# HT32F52342_52 register map
File version: 1.0
The register description for the Holtek HT32F52342/52352
CPU: CM0+ r0p1, little endian, no MPU, no FPU, 4 interrupt priority bits
Registers are 32-bit, read-write, reset 0x0 unless marked. A register's access mark holds for its fields unless they carry their own. Offsets are from the block's base; lines under a group give offsets from that group; [hi:lo] are bit positions; {n}, {i} and the like mark numbered series; 'fields as' and 'values as' point back to an identical list; <NAME> marks a mode.

## Memory map
0x40000000 USART0 size 0x1000
0x40001000 UART0 size 0x1000
0x40004000 SPI0 size 0x1000
0x40010000 ADC size 0x1000
0x40022000 AFIO size 0x1000
0x40024000 EXTI size 0x1000
0x40026000 I2S size 0x1000
0x4002C000 MCTM0 size 0x1000
0x40034000 SCTM0 size 0x1000
0x40040000 USART1 size 0x1000
0x40041000 UART1 size 0x1000
0x40043000 SCI size 0x1000
0x40044000 SPI1 size 0x1000
0x40048000 I2C0 size 0x1000
0x40049000 I2C1 size 0x1000
0x40058000 CMP size 0x1000
0x40068000 WDT size 0x1000
0x4006A000 RTC size 0x1000
0x4006A100 PWRCU size 0x1000
0x4006E000 GPTM0 size 0x1000
0x4006F000 GPTM1 size 0x1000
0x40074000 SCTM1 size 0x1000
0x40076000 BFTM0 size 0x1000
0x40077000 BFTM1 size 0x1000
0x40080000 FMC size 0x1000
0x40088000 CKCU size 0x1000
0x40088100 RSTCU size 0x1000
0x4008A000 CRC size 0x1000
0x40090000 PDMA size 0x1000
0x40098000 EBI size 0x1000
0x400A8000 USB size 0x1000
0x400B0000 GPIOA size 0x1000
0x400B2000 GPIOB size 0x1000
0x400B4000 GPIOC size 0x1000
0x400B6000 GPIOD size 0x1000
0xE000E000 NVIC size 0x1000
0xE000E010 SysTick size 0x1000
0xE000ED00 SCB size 0x1000
0xE000ED30 Fault_Reports size 0x1000

## Interrupts
0 LVD_BOD (PWRCU)
1 RTC
2 FMC
3 EVWUP (PWRCU)
4 EXTI0_1 (EXTI)
5 EXTI2_3 (EXTI)
6 EXTI4_15 (EXTI)
7 CMP0_1 (CMP)
8 ADC
10 MCTM0
11 GPTM1
12 GPTM0
13 SCTM0
14 SCTM1
17 BFTM0
18 BFTM1
19 I2C0
20 I2C1
21 SPI0
22 SPI1
23 USART0
24 USART1
25 UART0
26 UART1
27 SCI
28 I2S
29 USB
30 PDMACH0_1 (PDMA)
31 PDMACH2_5 (PDMA)

## NVIC
Base 0xE000E000
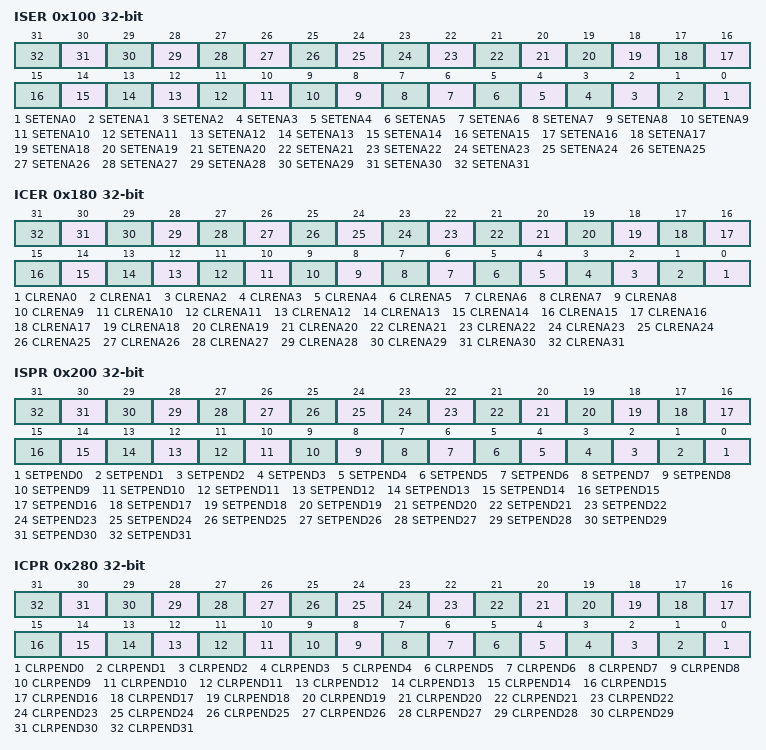
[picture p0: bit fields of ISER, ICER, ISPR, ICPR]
0x100 ISER
  [n] SETENA{n} (n=0..31)
0x180 ICER
  [n] CLRENA{n} (n=0..31)
0x200 ISPR
  [n] SETPEND{n} (n=0..31)
0x280 ICPR
  [n] CLRPEND{n} (n=0..31)
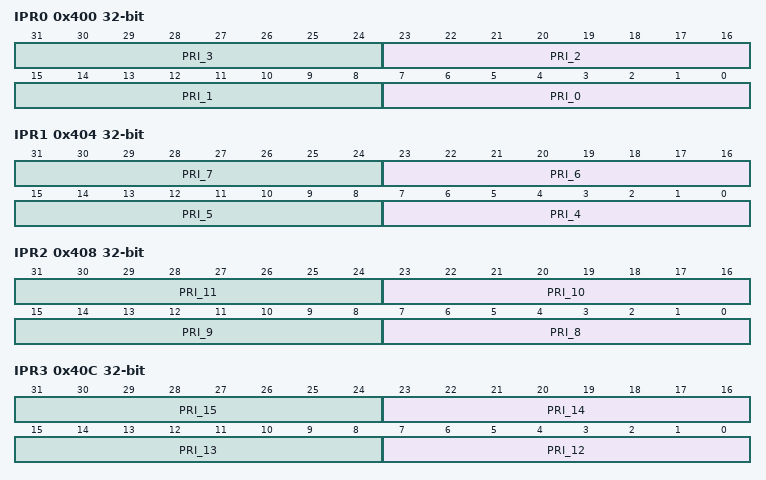
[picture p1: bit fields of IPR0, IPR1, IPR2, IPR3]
0x400 IPR0
  [8n+7:8n] PRI_{n} (n=0..3)
0x404 IPR1
  [8n-25:8n-32] PRI_{n} (n=4..7)
0x408 IPR2
  [8n-57:8n-64] PRI_{n} (n=8..11)
0x40C IPR3
  [8n-89:8n-96] PRI_{n} (n=12..15)
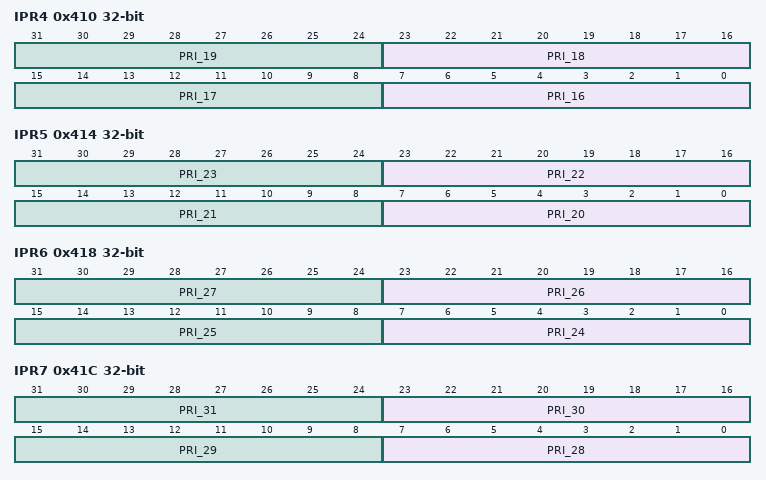
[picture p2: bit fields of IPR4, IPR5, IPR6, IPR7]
0x410 IPR4
  [8n-121:8n-128] PRI_{n} (n=16..19)
0x414 IPR5
  [8n-153:8n-160] PRI_{n} (n=20..23)
0x418 IPR6
  [8n-185:8n-192] PRI_{n} (n=24..27)
0x41C IPR7
  [8n-217:8n-224] PRI_{n} (n=28..31)

## SCB
Base 0xE000ED00
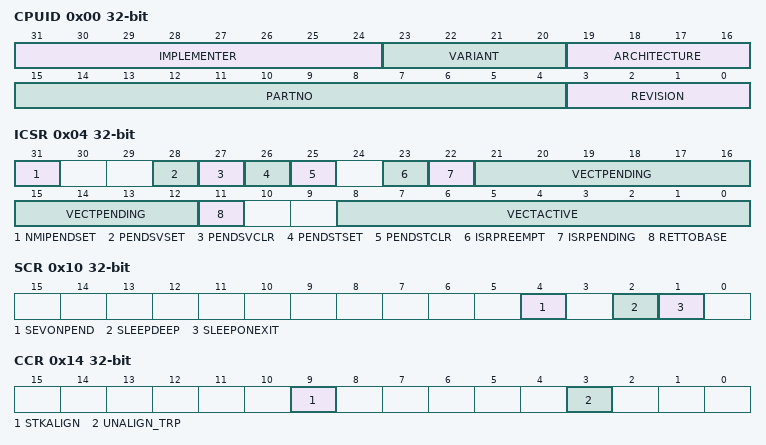
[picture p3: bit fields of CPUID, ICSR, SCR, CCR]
0x00 CPUID
  [31:24] IMPLEMENTER, [23:20] VARIANT, [19:16] ARCHITECTURE, [15:4] PARTNO, [3:0] REVISION
0x04 ICSR
  [31] NMIPENDSET, [28] PENDSVSET, [27] PENDSVCLR, [26] PENDSTSET, [25] PENDSTCLR, [23] ISRPREEMPT, [22] ISRPENDING, [21:12] VECTPENDING, [11] RETTOBASE, [8:0] VECTACTIVE
0x08 VTOR
  [31:7] TBLOFF
0x10 SCR
  [4] SEVONPEND, [2] SLEEPDEEP, [1] SLEEPONEXIT
0x14 CCR
  [9] STKALIGN, [3] UNALIGN_TRP
0x1C SHP2 — SHPR2
  [31:30] PRI_11
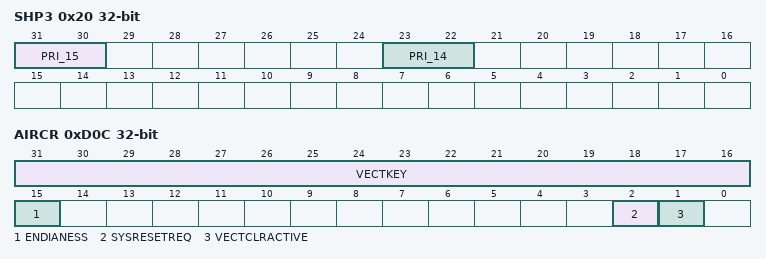
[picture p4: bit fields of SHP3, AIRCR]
0x20 SHP3 — SHPR3
  [31:30] PRI_15, [23:22] PRI_14
0xD0C AIRCR
  [31:16] VECTKEY, [15] ENDIANESS, [2] SYSRESETREQ, [1] VECTCLRACTIVE
0xD24 SHCSR
  [15] SVCALLPENDED

## SysTick
Base 0xE000E010
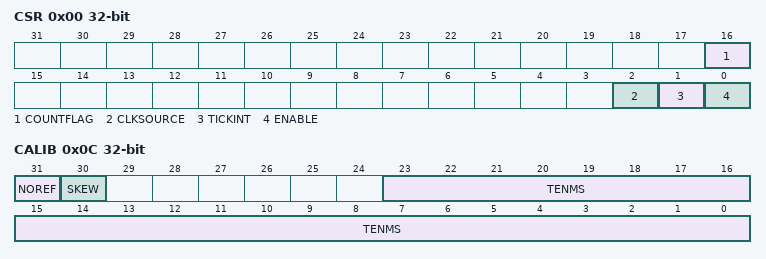
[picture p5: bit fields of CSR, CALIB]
0x00 CSR
  [16] COUNTFLAG, [2] CLKSOURCE, [1] TICKINT, [0] ENABLE
0x04 RVR
  [23:0] RELOAD
0x08 CVR
  [23:0] CURRENT
0x0C CALIB
  [31] NOREF, [30] SKEW, [23:0] TENMS

## Fault_Reports
Base 0xE000ED30
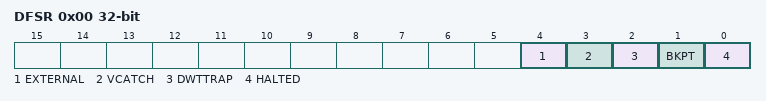
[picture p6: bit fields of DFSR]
0x00 DFSR
  [4] EXTERNAL, [3] VCATCH, [2] DWTTRAP, [1] BKPT, [0] HALTED

## FMC
Base 0x40080000
0x00 FMC_TADR
  [31:0] TADB
0x04 FMC_WRDR
  [31:0] WRDB
0x0C FMC_OCMR
  [3:0] CMD
0x10 FMC_OPCR
  [4:1] OPM
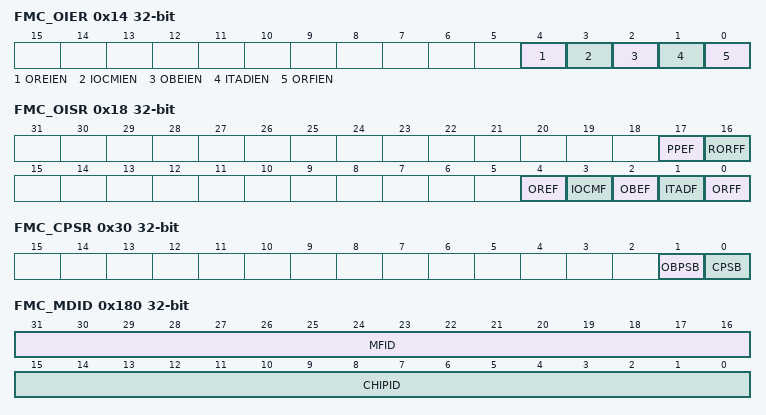
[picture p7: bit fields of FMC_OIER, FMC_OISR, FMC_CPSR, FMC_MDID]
0x14 FMC_OIER
  [4] OREIEN, [3] IOCMIEN, [2] OBEIEN, [1] ITADIEN, [0] ORFIEN
0x18 FMC_OISR
  [17] PPEF, [16] RORFF, [4] OREF, [3] IOCMF, [2] OBEF, [1] ITADF, [0] ORFF
{0x20+4i} FMC_PPSR{i} (i=0..3)
  [31:0] PPSB
0x30 FMC_CPSR
  [1] OBPSB, [0] CPSB
0x100 FMC_VMCR
  [1] VMCB
0x180 FMC_MDID
  [31:16] MFID, [15:0] CHIPID
0x184 FMC_PNSR
  [31:0] PNSB
0x188 FMC_PSSR
  [31:0] PSSB
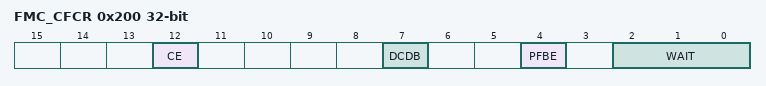
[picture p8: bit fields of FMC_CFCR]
0x200 FMC_CFCR
  [12] CE, [7] DCDB, [4] PFBE, [2:0] WAIT
{0x310+4i} FMC_CID{i} (i=0..3)
  [31:0] CID

## Notices in the file
Copyright (C) 2010 ARM Limited. All rights reserved.
ARM Limited (ARM) is supplying this SVD description for use with Cortex-M3
processor based microcontrollers.  This file and or content can be freely
distributed within development tools that are supporting such ARM based
processors.
THIS SOFTWARE IS PROVIDED "AS IS".  NO WARRANTIES, WHETHER EXPRESS, IMPLIED
OR STATUTORY, INCLUDING, BUT NOT LIMITED TO, IMPLIED WARRANTIES OF
MERCHANTABILITY AND FITNESS FOR A PARTICULAR PURPOSE APPLY TO THIS SOFTWARE.
ARM SHALL NOT, IN ANY CIRCUMSTANCES, BE LIABLE FOR SPECIAL, INCIDENTAL, OR
CONSEQUENTIAL DAMAGES, FOR ANY REASON WHATSOEVER.
